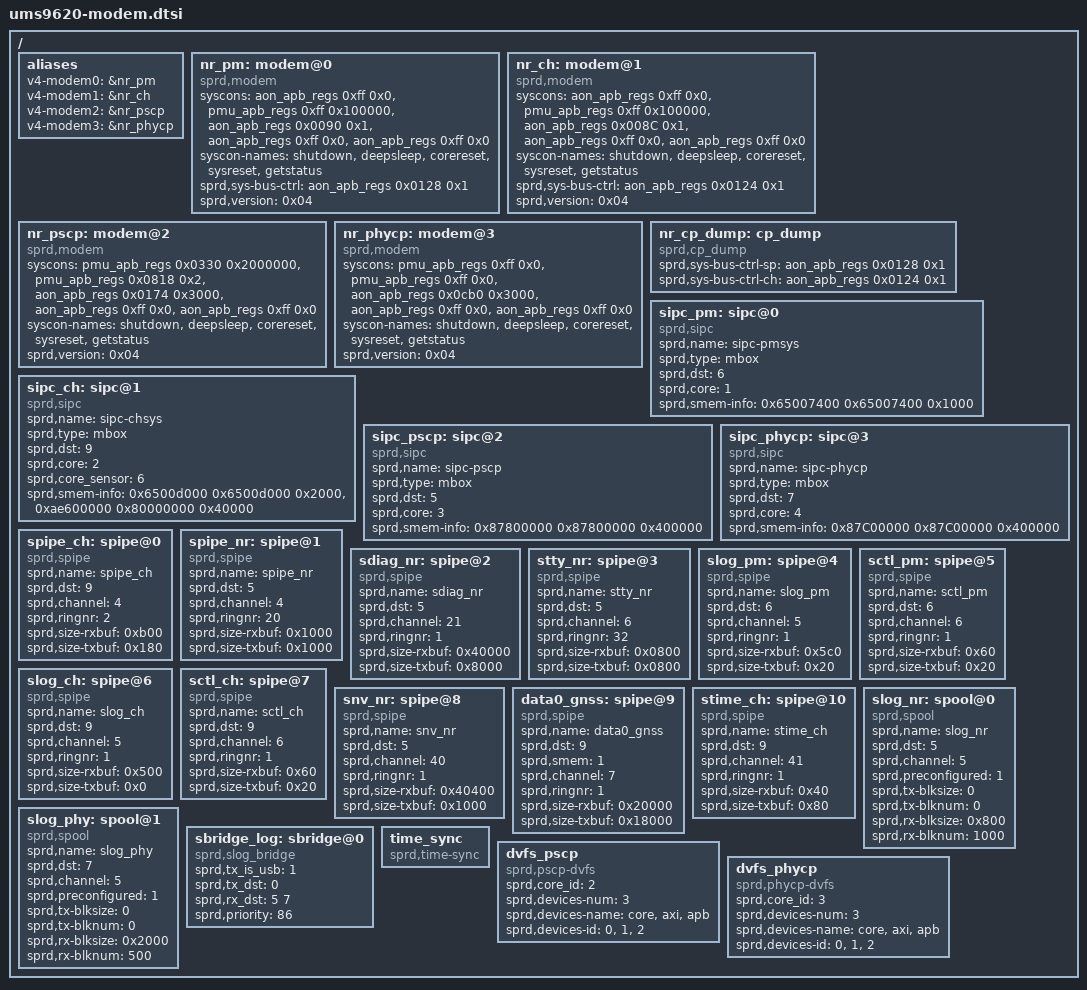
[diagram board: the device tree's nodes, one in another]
/*
 * Spreadtrum Sharkl6Pro modem board DTSI file
 * These dt is used for modem drivers
 *
 * Copyright (C) 2020, Spreadtrum Communications Inc.
 *
 * This file is licensed under a dual GPLv2 or X11 license.
 */

/ {
	aliases {
		v4-modem0 = &nr_pm;
		v4-modem1 = &nr_ch;
		v4-modem2 = &nr_pscp;
		v4-modem3 = &nr_phycp;
	};

	nr_pm: modem@0 {
		compatible = "sprd,modem";
		syscons = <&aon_apb_regs 0xff 0x0>,
				<&pmu_apb_regs 0xff 0x100000>,
				<&aon_apb_regs 0x0090 0x1>,
				<&aon_apb_regs 0xff 0x0>,
				<&aon_apb_regs 0xff 0x0>;
		syscon-names = "shutdown", "deepsleep", "corereset",
					"sysreset", "getstatus";
		sprd,sys-bus-ctrl = <&aon_apb_regs 0x0128 0x1>;
		sprd,version = <0x04>;
	};

	nr_ch: modem@1 {
		compatible = "sprd,modem";
		syscons = <&aon_apb_regs 0xff 0x0>,
				<&pmu_apb_regs 0xff 0x100000>,
				<&aon_apb_regs 0x008C 0x1>,
				<&aon_apb_regs 0xff 0x0>,
				<&aon_apb_regs 0xff 0x0>;
		syscon-names = "shutdown", "deepsleep", "corereset",
					"sysreset", "getstatus";
		sprd,sys-bus-ctrl = <&aon_apb_regs 0x0124 0x1>;
		sprd,version = <0x04>;
	};

	nr_pscp: modem@2 {
		compatible = "sprd,modem";
		syscons = <&pmu_apb_regs 0x0330 0x2000000>,
				<&pmu_apb_regs 0x0818 0x2>,
				<&aon_apb_regs 0x0174 0x3000>,
				<&aon_apb_regs 0xff 0x0>,
				<&aon_apb_regs 0xff 0x0>;
		syscon-names = "shutdown", "deepsleep", "corereset",
					"sysreset", "getstatus";
		sprd,version = <0x04>;
	};

	nr_phycp: modem@3 {
		compatible = "sprd,modem";
		syscons = <&pmu_apb_regs 0xff 0x0>,
				<&pmu_apb_regs 0xff 0x0>,
				<&aon_apb_regs 0x0cb0 0x3000>,
				<&aon_apb_regs 0xff 0x0>,
				<&aon_apb_regs 0xff 0x0>;
		syscon-names = "shutdown", "deepsleep", "corereset",
					"sysreset", "getstatus";
		sprd,version = <0x04>;
	};

	nr_cp_dump: cp_dump {
		compatible = "sprd,cp_dump";
		sprd,sys-bus-ctrl-sp = <&aon_apb_regs 0x0128 0x1>;
		sprd,sys-bus-ctrl-ch = <&aon_apb_regs 0x0124 0x1>;
	};

	sipc_pm: sipc@0 {
		compatible = "sprd,sipc";
		sprd,name = "sipc-pmsys";
		sprd,type = "mbox";
		sprd,dst = <6>;
		sprd,core = <1>;
		/* <ap-addr dst-maped-addr size> */
		sprd,smem-info = <0x65007400 0x65007400 0x1000>;
	};

	sipc_ch: sipc@1 {
		compatible = "sprd,sipc";
		sprd,name = "sipc-chsys";
		sprd,type = "mbox";
		sprd,dst = <9>;
		sprd,core = <2>;
		sprd,core_sensor = <6>;
		/* <ap-addr dst-maped-addr size> */
		sprd,smem-info = <0x6500d000 0x6500d000 0x2000>,
				 <0xae600000 0x80000000 0x40000>;
	};

	sipc_pscp: sipc@2 {
		compatible = "sprd,sipc";
		sprd,name = "sipc-pscp";
		sprd,type = "mbox";
		sprd,dst = <5>;
		sprd,core = <3>;
		/* <ap-addr dst-maped-addr size> */
		sprd,smem-info = <0x87800000 0x87800000 0x400000>;
	};

	sipc_phycp: sipc@3 {
		compatible = "sprd,sipc";
		sprd,name = "sipc-phycp";
		sprd,type = "mbox";
		sprd,dst = <7>;
		sprd,core = <4>;
		/* <ap-addr dst-maped-addr size> */
		sprd,smem-info = <0x87C00000 0x87C00000 0x400000>;
	};

	spipe_ch: spipe@0 {
		compatible = "sprd,spipe";
		sprd,name = "spipe_ch";
		sprd,dst = <9>;
		sprd,channel = <4>;
		sprd,ringnr = <2>;
		sprd,size-rxbuf = <0xb00>;
		sprd,size-txbuf = <0x180>;
	};

	spipe_nr: spipe@1 {
		compatible = "sprd,spipe";
		sprd,name = "spipe_nr";
		sprd,dst = <5>;
		sprd,channel = <4>;
		sprd,ringnr = <20>;
		sprd,size-rxbuf = <0x1000>; /* 4*1024 */
		sprd,size-txbuf = <0x1000>; /* 4*1024 */
	};

	sdiag_nr: spipe@2 {
		compatible = "sprd,spipe";
		sprd,name = "sdiag_nr";
		sprd,dst = <5>;
		sprd,channel = <21>;
		sprd,ringnr = <1>;
		sprd,size-rxbuf = <0x40000>; /* 256*1024*/
		sprd,size-txbuf = <0x8000>; /* 32*1024 */
	};

	stty_nr: spipe@3 {
		compatible = "sprd,spipe";
		sprd,name = "stty_nr";
		sprd,dst = <5>;
		sprd,channel = <6>;
		sprd,ringnr = <32>;
		sprd,size-rxbuf = <0x0800>; /* 2*1024*/
		sprd,size-txbuf = <0x0800>; /* 2*1024 */
	};

	slog_pm: spipe@4 {
		compatible = "sprd,spipe";
		sprd,name = "slog_pm";
		sprd,dst = <6>;
		sprd,channel = <5>;
		sprd,ringnr = <1>;
		sprd,size-rxbuf = <0x5c0>;
		sprd,size-txbuf = <0x20>;
	};

	sctl_pm: spipe@5 {
		compatible = "sprd,spipe";
		sprd,name = "sctl_pm";
		sprd,dst = <6>;
		sprd,channel = <6>;
		sprd,ringnr = <1>;
		sprd,size-rxbuf = <0x60>;
		sprd,size-txbuf = <0x20>;
	};

	slog_ch: spipe@6 {
		compatible = "sprd,spipe";
		sprd,name = "slog_ch";
		sprd,dst = <9>;
		sprd,channel = <5>;
		sprd,ringnr = <1>;
		sprd,size-rxbuf = <0x500>;
		sprd,size-txbuf = <0x0>;
	};

	sctl_ch: spipe@7 {
		compatible = "sprd,spipe";
		sprd,name = "sctl_ch";
		sprd,dst = <9>;
		sprd,channel = <6>;
		sprd,ringnr = <1>;
		sprd,size-rxbuf = <0x60>;
		sprd,size-txbuf = <0x20>;
	};

	snv_nr: spipe@8 {
		compatible = "sprd,spipe";
		sprd,name = "snv_nr";
		sprd,dst = <5>;
		sprd,channel = <40>;
		sprd,ringnr = <1>;
		sprd,size-rxbuf = <0x40400>; /* 257*1024*/
		sprd,size-txbuf = <0x1000>; /* 4*1024 */
	};

	data0_gnss: spipe@9 {
		compatible = "sprd,spipe";
		sprd,name = "data0_gnss";
		sprd,dst = <9>;
		sprd,smem = <1>;
		sprd,channel = <7>;
		sprd,ringnr = <1>;
		sprd,size-rxbuf = <0x20000>;
		sprd,size-txbuf = <0x18000>;
	};

	stime_ch: spipe@10 {
		compatible = "sprd,spipe";
		sprd,name = "stime_ch";
		sprd,dst = <9>;
		sprd,channel = <41>;
		sprd,ringnr = <1>;
		sprd,size-rxbuf = <0x40>;
		sprd,size-txbuf = <0x80>;
	};

	slog_nr: spool@0{
		compatible = "sprd,spool";
		sprd,name = "slog_nr";
		sprd,dst = <5>;
		sprd,channel = <5>;
		sprd,preconfigured = <1>;
		sprd,tx-blksize = <0>;
		sprd,tx-blknum = <0>;
		sprd,rx-blksize = <0x800>;
		sprd,rx-blknum = <1000>;
	};

	slog_phy: spool@1{
		compatible = "sprd,spool";
		sprd,name = "slog_phy";
		sprd,dst = <7>;
		sprd,channel = <5>;
		sprd,preconfigured = <1>;
		sprd,tx-blksize = <0>;
		sprd,tx-blknum = <0>;
		sprd,rx-blksize = <0x2000>;
		sprd,rx-blknum = <500>;
	};

	sbridge_log: sbridge@0 {
		compatible = "sprd,slog_bridge";
		sprd,tx_is_usb = <1>;
		sprd,tx_dst = <0>;
		sprd,rx_dst = <5 7>;
		sprd,priority = <86>;
	};

	time_sync {
		compatible = "sprd,time-sync";
	};

	dvfs_pscp {
		compatible = "sprd,pscp-dvfs";
		sprd,core_id = <2>;
		sprd,devices-num = <3>;
		sprd,devices-name = "core", "axi", "apb";
		sprd,devices-id = <0>, <1>, <2>;
	};

	dvfs_phycp {
		compatible = "sprd,phycp-dvfs";
		sprd,core_id = <3>;
		sprd,devices-num = <3>;
		sprd,devices-name = "core", "axi", "apb";
		sprd,devices-id = <0>, <1>, <2>;
	};
};
